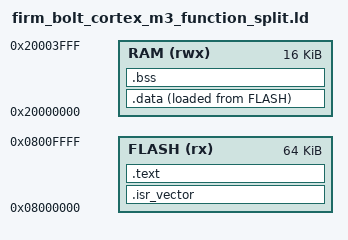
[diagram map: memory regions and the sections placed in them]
ENTRY(Reset_Handler)

MEMORY
{
  FLASH (rx)  : ORIGIN = 0x08000000, LENGTH = 64K
  RAM   (rwx) : ORIGIN = 0x20000000, LENGTH = 16K
}

SECTIONS
{
  .isr_vector ORIGIN(FLASH) :
  {
    KEEP(*(.isr_vector))
  } > FLASH

  .text ORIGIN(FLASH) + 0x100 :
  {
    *(.text*)
    /* Qualified capacity for the one cross-fragment branch introduced by
       the splitter.  The production gate requires the final extent to match
       this linker-owned range exactly. */
    . = . + 4;
  } > FLASH

  .data :
  {
    *(.data*)
  } > RAM AT > FLASH

  .bss (NOLOAD) :
  {
    *(.bss*)
    *(COMMON)
  } > RAM
}
